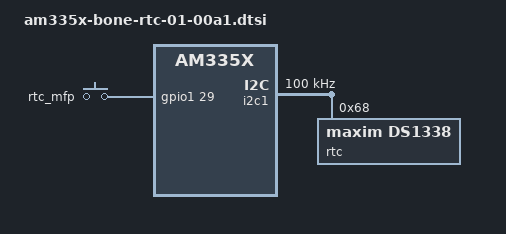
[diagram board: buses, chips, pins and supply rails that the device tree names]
/*
 * Copyright (C) 2012 Texas Instruments Incorporated - http://www.ti.com/
 *
 * This program is free software; you can redistribute it and/or modify
 * it under the terms of the GNU General Public License version 2 as
 * published by the Free Software Foundation.
 */

&ocp {
	P8_26_pinmux {
		/* gpio1[29] */
		status = "disabled";
	};
};

/ {
	gpio_keys {
		compatible = "gpio-keys";
		pinctrl-names = "default";
		pinctrl-0 = <&gpio1_29_pins>;

		#address-cells = <1>;
		#size-cells = <0>;

		rtc_mfp@1 {
			label = "rtc_mfp";
			gpios = <&gpio1 29 GPIO_ACTIVE_HIGH>;
			linux,code = <143>; /* System Wake Up */
			gpio-key,wakeup;
		};
	};
};

&i2c1 {
	pinctrl-names = "default";
	pinctrl-0 = <&i2c1_pins>;

	status = "okay";
	clock-frequency = <100000>;

	/* MCP79410 RTC module */
	rtc@68 {
		compatible = "maxim,ds1338";
		reg = <0x68>;
	};
};
